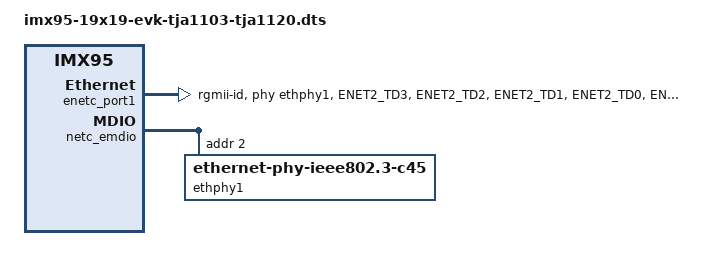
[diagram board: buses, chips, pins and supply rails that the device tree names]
// SPDX-License-Identifier: (GPL-2.0+ OR MIT)
/*
 * Copyright 2023 NXP
 */

#include "imx95-19x19-evk.dts"

/ {
	aliases {
		ethernet2 = &enetc_port1;
	};
};

&enetc_port1 {
	pinctrl-names = "default";
	pinctrl-0 = <&pinctrl_enetc1>;
	phy-handle = <&ethphy1>;
	phy-mode = "rgmii-id";
	status = "okay";
};

&netc_prb_ierb {
	netc-interfaces = <NXP_NETC_RGMII
			   NXP_NETC_RGMII
			   NXP_NETC_SERIAL>;
};

&netc_emdio {
	ethphy1: ethernet-phy@2 {
		compatible = "ethernet-phy-ieee802.3-c45";
		/* PHY ADDR Configuration
		 * CONFIG0: 1-2 CONFIG1: 1-2 CONFIG2: 2-3
		 */
		reg = <2>;
		tx-internal-delay-ps = <1800>;
		rx-internal-delay-ps = <1666>;
	};
};

&scmi_iomuxc {
	pinctrl_enetc1: enetc1grp {
		fsl,pins = <
			IMX95_PAD_ENET2_TD3__NETCMIX_TOP_ETH1_RGMII_TD3		0x57e
			IMX95_PAD_ENET2_TD2__NETCMIX_TOP_ETH1_RGMII_TD2		0x57e
			IMX95_PAD_ENET2_TD1__NETCMIX_TOP_ETH1_RGMII_TD1		0x57e
			IMX95_PAD_ENET2_TD0__NETCMIX_TOP_ETH1_RGMII_TD0		0x57e
			IMX95_PAD_ENET2_TX_CTL__NETCMIX_TOP_ETH1_RGMII_TX_CTL	0x57e
			IMX95_PAD_ENET2_TXC__NETCMIX_TOP_ETH1_RGMII_TX_CLK	0x5fe
			IMX95_PAD_ENET2_RX_CTL__NETCMIX_TOP_ETH1_RGMII_RX_CTL	0x57e
			IMX95_PAD_ENET2_RXC__NETCMIX_TOP_ETH1_RGMII_RX_CLK	0x5fe
			IMX95_PAD_ENET2_RD0__NETCMIX_TOP_ETH1_RGMII_RD0		0x57e
			IMX95_PAD_ENET2_RD1__NETCMIX_TOP_ETH1_RGMII_RD1		0x57e
			IMX95_PAD_ENET2_RD2__NETCMIX_TOP_ETH1_RGMII_RD2		0x57e
			IMX95_PAD_ENET2_RD3__NETCMIX_TOP_ETH1_RGMII_RD3		0x57e
		>;
	};
};
